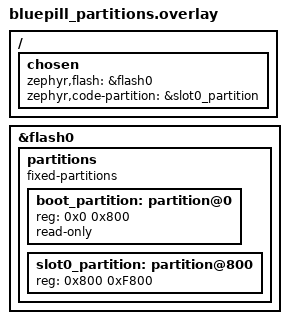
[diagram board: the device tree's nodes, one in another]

/ {
    chosen {
        zephyr,flash = &flash0;
        zephyr,code-partition = &slot0_partition;
    };
};

&flash0 {
    partitions {
        compatible = "fixed-partitions";
        #address-cells = <0x1>;
        #size-cells = <0x1>;

        boot_partition: partition@0 {
            reg = <0x0 0x800>;
            read-only;
        };

        slot0_partition: partition@800 {
            reg = <0x800 0xF800>;
        };
    };
};
